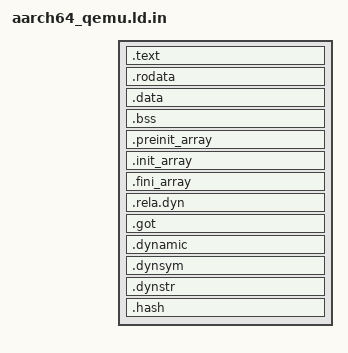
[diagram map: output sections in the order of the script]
OUTPUT_ARCH(aarch64)
ENTRY(_start)

/* Separate loadable segments, so the image itself obeys W^X.
 *
 * The sections below were already page-aligned and distinct, but alignment is
 * not separation: with no PHDRS the linker is free to place them all in one
 * PT_LOAD whose permissions are the union of everything inside it. That union
 * is read, write and execute at once, and ld says so - "has a LOAD segment with
 * RWX permissions" - which this build treats as an error rather than a warning.
 *
 * It was right to. M7.4a requires that no page the kernel maps be both writable
 * and executable, and M7.4b enforces that for mappings the kernel creates at
 * runtime. None of that helps if the image the machine loads before any of our
 * code runs is itself one RWX blob: the very first thing in memory would be the
 * thing the rule exists to forbid.
 *
 * Flags are the ELF program-header bits: PF_R = 4, PF_W = 2, PF_X = 1.
 */
PHDRS
{
    text   PT_LOAD FLAGS(5); /* R + X, never writable */
    rodata PT_LOAD FLAGS(4); /* R only - constants are not data to be changed */
    data   PT_LOAD FLAGS(6); /* R + W, never executable */
}

SECTIONS
{
    . = @EMNL_AARCH64_BOOT_LOAD_ADDRESS@;
    __cookie_image_start = .;

    /* The ARM64 Image header's text_offset, derived here rather than written
     * into aarch64_start.S by hand.
     *
     * The two used to be independent and were wrong: the header declared
     * 0x80000 while the image linked at 0x40200000, so a loader honouring the
     * header placed Cookie 1.5 MiB below where its absolute references point.
     * Nothing caught it, because the boot proof loads the ELF by program
     * headers and never reads this field - the one field a phone would use is
     * the one no gate exercised.
     *
     * Deriving it makes disagreement unrepresentable. The assertions below are
     * the remaining ways a port could still be wrong, and each is a build
     * failure rather than a boot failure. */
    __cookie_ram_base = @EMNL_AARCH64_BOOT_RAM_BASE@;
    __cookie_text_offset = __cookie_image_start - __cookie_ram_base;
    ASSERT(__cookie_image_start >= __cookie_ram_base,
        "Cookie image is linked below the declared base of RAM")
    ASSERT((__cookie_ram_base & 0x1FFFFF) == 0,
        "Cookie RAM base must be 2 MiB aligned, per the AArch64 Image contract")
    ASSERT((__cookie_text_offset & 0xFFFF) == 0,
        "Cookie text_offset must be 64 KiB aligned, per the AArch64 Image contract")

    .text ALIGN(4096) : {
        __cookie_text_start = .;
        KEEP(*(.text.boot))
        *(.text .text.*)
        __cookie_text_end = ALIGN(4096);
        . = __cookie_text_end;
    } :text

    .rodata ALIGN(4096) : {
        __cookie_rodata_start = .;
        *(.rodata .rodata.*)
        __cookie_rodata_end = ALIGN(4096);
        . = __cookie_rodata_end;
    } :rodata

    .data ALIGN(4096) : {
        __cookie_data_start = .;
        *(.data .data.*)
        __cookie_data_end = ALIGN(4096);
        . = __cookie_data_end;
    } :data

    /* NOLOAD, but still part of the writable segment: it is memory the kernel
     * writes and must never be memory the kernel executes. */
    .bss ALIGN(4096) (NOLOAD) : {
        __bss_start = .;
        *(.bss.boot_stack)
        *(.bss .bss.* COMMON)
        __bss_end = ALIGN(4096);
        . = __bss_end;
    } :data

    /* Cookie's native image deliberately has no C/C++ startup runtime. Keep
       these sections visible to the linker and fail if any object introduces a
       constructor/destructor instead of silently discarding code that somebody
       expected to execute. */
    .preinit_array ALIGN(8) : { KEEP(*(.preinit_array .preinit_array.*)) } :data
    .init_array ALIGN(8) : { KEEP(*(.init_array .init_array.*)) } :data
    .fini_array ALIGN(8) : { KEEP(*(.fini_array .fini_array.*)) } :data
    ASSERT(SIZEOF(.preinit_array) == 0, "Cookie kernel cannot require preinit runtime")
    ASSERT(SIZEOF(.init_array) == 0, "Cookie kernel cannot require global constructors")
    ASSERT(SIZEOF(.fini_array) == 0, "Cookie kernel cannot require global destructors")

    __cookie_image_end = .;
    __cookie_image_size = __cookie_image_end - __cookie_image_start;

    /* Dynamic-linking machinery a -pie link produces and a freestanding image
     * has no use for. Kept visible rather than silently discarded: .rela.dyn is
     * the one that matters, and it is asserted empty rather than dropped,
     * because dropping it would turn "this image needs no relocations" from a
     * checked property into a hope. */
    .rela.dyn ALIGN(8) : {
        __cookie_rela_start = .;
        *(.rela .rela.*)
        __cookie_rela_end = .;
    } :data
    /* Not asserted empty. The first attempt required zero relocations, which
     * would have made "no file-scope object may hold a pointer to another one"
     * a standing constraint on every future line of kernel code. _start applies
     * them instead; what the build asserts is the type, in the workflow, since
     * the loop implements exactly one and skipping an unimplemented type
     * silently is the dangerous outcome. */

    /* Kept and asserted empty rather than discarded. A -pie link produces these
     * whether or not anything uses them, and discarding an output section the
     * linker still holds references into fails the link with a message about
     * the discard rather than about the cause - which is how the first attempt
     * at this hid its own reason.
     *
     * Asserting empty says the thing worth saying: every symbol reference in
     * this image is PC-relative, so there is no table of absolute addresses to
     * fix up at load time. -fvisibility=hidden is what makes that true. */
    /* The GOT is writable data holding absolute addresses, so it is relocated
     * like everything else rather than eliminated. -fvisibility=hidden removes
     * most of it; what remains is symbols defined in assembly that C++ only
     * declares, which the compiler cannot know are local. */
    .got ALIGN(8) : {
        __cookie_got_start = .;
        *(.got .got.plt)
        __cookie_got_end = .;
    } :data

    .dynamic ALIGN(8) : { *(.dynamic) } :data
    .dynsym  ALIGN(8) : { *(.dynsym) } :data
    .dynstr  ALIGN(8) : { *(.dynstr) } :data
    .hash    ALIGN(8) : { *(.hash) *(.gnu.hash) } :data

    /DISCARD/ : {
        *(.comment)
        *(.note .note.*)
        *(.eh_frame .eh_frame.*)
        *(.gcc_except_table .gcc_except_table.*)
        *(.interp)
    }
}
